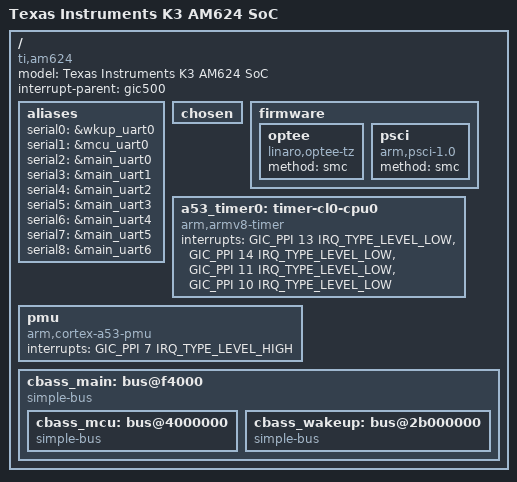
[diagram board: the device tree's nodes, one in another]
// SPDX-License-Identifier: GPL-2.0
/*
 * Device Tree Source for AM62 SoC Family
 *
 * Copyright (C) 2021 Texas Instruments Incorporated - https://www.ti.com/
 */

#include <dt-bindings/gpio/gpio.h>
#include <dt-bindings/interrupt-controller/irq.h>
#include <dt-bindings/interrupt-controller/arm-gic.h>
#include <dt-bindings/pinctrl/k3.h>
#include <dt-bindings/soc/ti,sci_pm_domain.h>

/ {
	model = "Texas Instruments K3 AM624 SoC";
	compatible = "ti,am624";
	interrupt-parent = <&gic500>;
	#address-cells = <2>;
	#size-cells = <2>;

	aliases {
		serial0 = &wkup_uart0;
		serial1 = &mcu_uart0;
		serial2 = &main_uart0;
		serial3 = &main_uart1;
		serial4 = &main_uart2;
		serial5 = &main_uart3;
		serial6 = &main_uart4;
		serial7 = &main_uart5;
		serial8 = &main_uart6;
	};

	chosen { };

	firmware {
		optee {
			compatible = "linaro,optee-tz";
			method = "smc";
		};

		psci: psci {
			compatible = "arm,psci-1.0";
			method = "smc";
		};
	};

	a53_timer0: timer-cl0-cpu0 {
		compatible = "arm,armv8-timer";
		interrupts = <GIC_PPI 13 IRQ_TYPE_LEVEL_LOW>, /* cntpsirq */
			     <GIC_PPI 14 IRQ_TYPE_LEVEL_LOW>, /* cntpnsirq */
			     <GIC_PPI 11 IRQ_TYPE_LEVEL_LOW>, /* cntvirq */
			     <GIC_PPI 10 IRQ_TYPE_LEVEL_LOW>; /* cnthpirq */
	};

	pmu: pmu {
		compatible = "arm,cortex-a53-pmu";
		interrupts = <GIC_PPI 7 IRQ_TYPE_LEVEL_HIGH>;
	};

	cbass_main: bus@f4000 {
		compatible = "simple-bus";
		#address-cells = <2>;
		#size-cells = <2>;

		ranges = <0x00 0x000f0000 0x00 0x000f0000 0x00 0x00030000>, /* Main MMRs */
			 <0x00 0x00600000 0x00 0x00600000 0x00 0x00001100>, /* GPIO */
			 <0x00 0x00703000 0x00 0x00703000 0x00 0x00000200>, /* USB0 debug trace */
			 <0x00 0x0070C000 0x00 0x0070C000 0x00 0x00000200>, /* USB1 debug trace */
			 <0x00 0x00a40000 0x00 0x00a40000 0x00 0x00000800>, /* Timesync router */

			 <0x00 0x01000000 0x00 0x01000000 0x00 0x01b28400>, /* First peripheral window */
			 <0x00 0x08000000 0x00 0x08000000 0x00 0x00200000>, /* Main CPSW */
			 <0x00 0x0e000000 0x00 0x0e000000 0x00 0x01d20000>, /* Second peripheral window */
			 <0x00 0x20000000 0x00 0x20000000 0x00 0x0a008000>, /* Third peripheral window */

			 /* TBD -> Do the rest - still churning */

			 /* MCU Domain Range */
			 <0x00 0x04000000 0x00 0x04000000 0x00 0x01ff1400>,

			 /* Wakeup Domain Range */
			 <0x00 0x2b000000 0x00 0x2b000000 0x00 0x00300400>;

		cbass_mcu: bus@4000000 {
			compatible = "simple-bus";
			#address-cells = <2>;
			#size-cells = <2>;
			ranges = <0x00 0x04000000 0x00 0x04000000 0x00 0x01ff1400>; /* Peripheral window */
		};

		cbass_wakeup: bus@2b000000 {
			compatible = "simple-bus";
			#address-cells = <2>;
			#size-cells = <2>;
			ranges = <0x00 0x2b000000 0x00 0x2b000000 0x00 0x00300400>; /* Peripheral Window */
		};
	};
};

/* Now include the peripherals for each bus segments */
#include "k3-am62-main.dtsi"
#include "k3-am62-mcu.dtsi"
#include "k3-am62-wakeup.dtsi"
